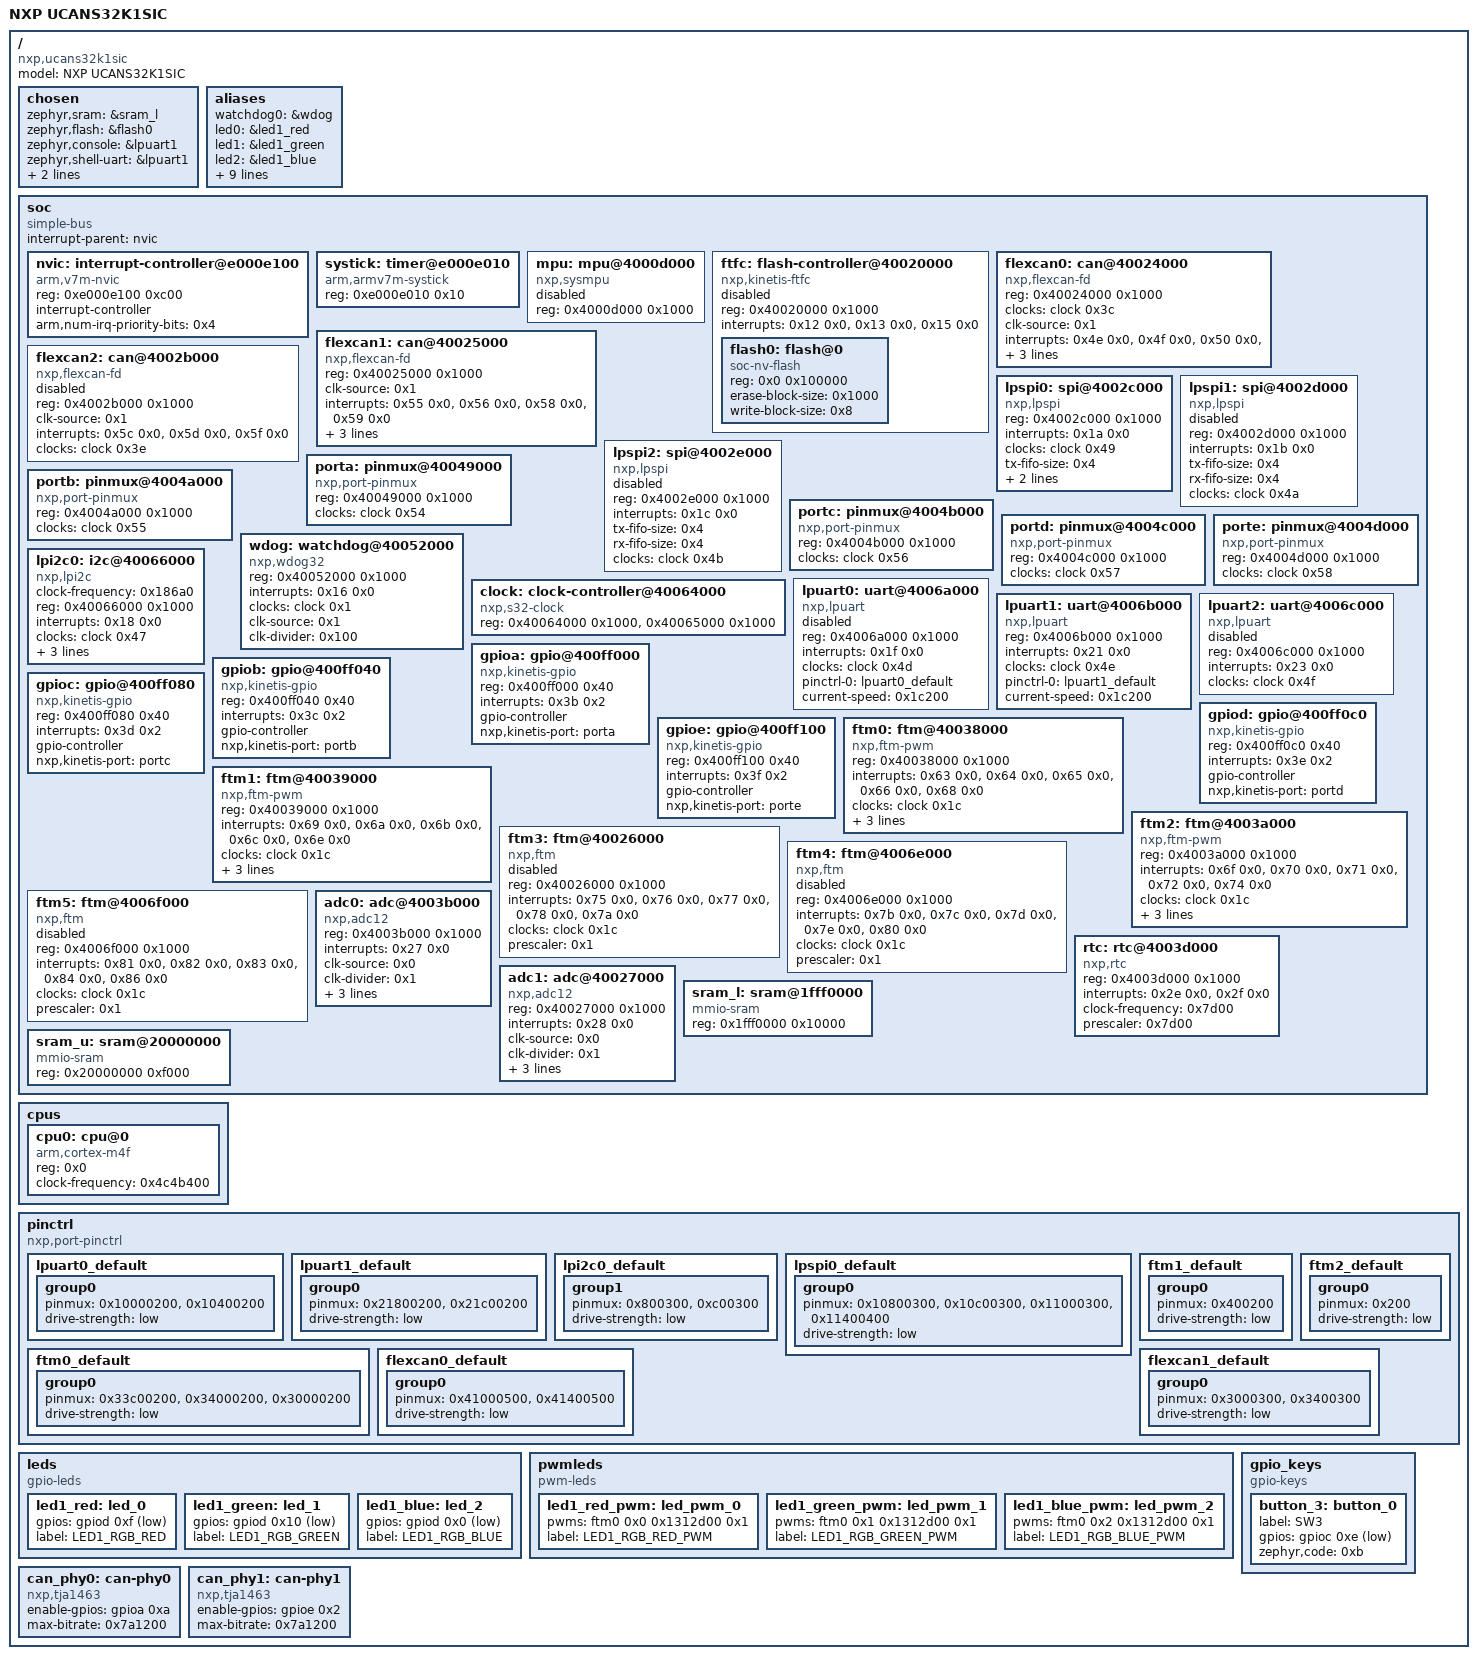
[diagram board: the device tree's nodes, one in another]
/dts-v1/;

/* node '/' defined in zephyr/dts/common/skeleton.dtsi:9 */
/ {
	#address-cells = < 0x1 >;        /* in zephyr/dts/common/skeleton.dtsi:10 */
	#size-cells = < 0x1 >;           /* in zephyr/dts/common/skeleton.dtsi:11 */
	model = "NXP UCANS32K1SIC";      /* in zephyr/boards/nxp/ucans32k1sic/ucans32k1sic.dts:15 */
	compatible = "nxp,ucans32k1sic"; /* in zephyr/boards/nxp/ucans32k1sic/ucans32k1sic.dts:16 */

	/* node '/chosen' defined in zephyr/dts/common/skeleton.dtsi:13 */
	chosen {
		zephyr,sram = &sram_l;        /* in zephyr/boards/nxp/ucans32k1sic/ucans32k1sic.dts:19 */
		zephyr,flash = &flash0;       /* in zephyr/boards/nxp/ucans32k1sic/ucans32k1sic.dts:20 */
		zephyr,console = &lpuart1;    /* in zephyr/boards/nxp/ucans32k1sic/ucans32k1sic.dts:21 */
		zephyr,shell-uart = &lpuart1; /* in zephyr/boards/nxp/ucans32k1sic/ucans32k1sic.dts:22 */
		zephyr,uart-pipe = &lpuart1;  /* in zephyr/boards/nxp/ucans32k1sic/ucans32k1sic.dts:23 */
		zephyr,canbus = &flexcan0;    /* in zephyr/boards/nxp/ucans32k1sic/ucans32k1sic.dts:24 */
	};

	/* node '/aliases' defined in zephyr/dts/common/skeleton.dtsi:15 */
	aliases {
		watchdog0 = &wdog;               /* in zephyr/dts/arm/nxp/nxp_s32k1xx.dtsi:14 */
		led0 = &led1_red;                /* in zephyr/boards/nxp/ucans32k1sic/ucans32k1sic.dts:28 */
		led1 = &led1_green;              /* in zephyr/boards/nxp/ucans32k1sic/ucans32k1sic.dts:29 */
		led2 = &led1_blue;               /* in zephyr/boards/nxp/ucans32k1sic/ucans32k1sic.dts:30 */
		pwm-led0 = &led1_red_pwm;        /* in zephyr/boards/nxp/ucans32k1sic/ucans32k1sic.dts:31 */
		pwm-led1 = &led1_green_pwm;      /* in zephyr/boards/nxp/ucans32k1sic/ucans32k1sic.dts:32 */
		pwm-led2 = &led1_blue_pwm;       /* in zephyr/boards/nxp/ucans32k1sic/ucans32k1sic.dts:33 */
		red-pwm-led = &led1_red_pwm;     /* in zephyr/boards/nxp/ucans32k1sic/ucans32k1sic.dts:34 */
		green-pwm-led = &led1_green_pwm; /* in zephyr/boards/nxp/ucans32k1sic/ucans32k1sic.dts:35 */
		blue-pwm-led = &led1_blue_pwm;   /* in zephyr/boards/nxp/ucans32k1sic/ucans32k1sic.dts:36 */
		pwm-0 = &ftm0;                   /* in zephyr/boards/nxp/ucans32k1sic/ucans32k1sic.dts:37 */
		sw0 = &button_3;                 /* in zephyr/boards/nxp/ucans32k1sic/ucans32k1sic.dts:38 */
		i2c-0 = &lpi2c0;                 /* in zephyr/boards/nxp/ucans32k1sic/ucans32k1sic.dts:39 */
	};

	/* node '/soc' defined in zephyr/dts/arm/armv7-m.dtsi:6 */
	soc {
		#address-cells = < 0x1 >;     /* in zephyr/dts/arm/armv7-m.dtsi:7 */
		#size-cells = < 0x1 >;        /* in zephyr/dts/arm/armv7-m.dtsi:8 */
		compatible = "simple-bus";    /* in zephyr/dts/arm/armv7-m.dtsi:9 */
		ranges;                       /* in zephyr/dts/arm/armv7-m.dtsi:11 */
		interrupt-parent = < &nvic >; /* in zephyr/dts/arm/nxp/nxp_s32k1xx.dtsi:34 */

		/* node '/soc/interrupt-controller@e000e100' defined in zephyr/dts/arm/armv7-m.dtsi:13 */
		nvic: interrupt-controller@e000e100 {
			#address-cells = < 0x1 >;            /* in zephyr/dts/arm/armv7-m.dtsi:14 */
			compatible = "arm,v7m-nvic";         /* in zephyr/dts/arm/armv7-m.dtsi:15 */
			reg = < 0xe000e100 0xc00 >;          /* in zephyr/dts/arm/armv7-m.dtsi:16 */
			interrupt-controller;                /* in zephyr/dts/arm/armv7-m.dtsi:17 */
			#interrupt-cells = < 0x2 >;          /* in zephyr/dts/arm/armv7-m.dtsi:18 */
			arm,num-irq-priority-bits = < 0x4 >; /* in zephyr/dts/arm/nxp/nxp_s32k146.dtsi:41 */
			phandle = < 0x1 >;                   /* in zephyr/dts/arm/nxp/nxp_s32k1xx.dtsi:34 */
		};

		/* node '/soc/timer@e000e010' defined in zephyr/dts/arm/armv7-m.dtsi:21 */
		systick: timer@e000e010 {
			compatible = "arm,armv7m-systick"; /* in zephyr/dts/arm/armv7-m.dtsi:22 */
			reg = < 0xe000e010 0x10 >;         /* in zephyr/dts/arm/armv7-m.dtsi:23 */
		};

		/* node '/soc/mpu@4000d000' defined in zephyr/dts/arm/nxp/nxp_s32k1xx.dtsi:36 */
		mpu: mpu@4000d000 {
			compatible = "nxp,sysmpu";   /* in zephyr/dts/arm/nxp/nxp_s32k1xx.dtsi:37 */
			reg = < 0x4000d000 0x1000 >; /* in zephyr/dts/arm/nxp/nxp_s32k1xx.dtsi:38 */
			status = "disabled";         /* in zephyr/dts/arm/nxp/nxp_s32k1xx.dtsi:39 */
		};

		/* node '/soc/flash-controller@40020000' defined in zephyr/dts/arm/nxp/nxp_s32k1xx.dtsi:42 */
		ftfc: flash-controller@40020000 {
			compatible = "nxp,kinetis-ftfc";      /* in zephyr/dts/arm/nxp/nxp_s32k1xx.dtsi:43 */
			reg = < 0x40020000 0x1000 >;          /* in zephyr/dts/arm/nxp/nxp_s32k1xx.dtsi:44 */
			interrupts = < 0x12 0x0 >,
			             < 0x13 0x0 >,
			             < 0x15 0x0 >;            /* in zephyr/dts/arm/nxp/nxp_s32k1xx.dtsi:45 */
			interrupt-names = "command-complete",
			                  "read-collision",
			                  "double-bit";       /* in zephyr/dts/arm/nxp/nxp_s32k1xx.dtsi:46 */
			#address-cells = < 0x1 >;             /* in zephyr/dts/arm/nxp/nxp_s32k1xx.dtsi:47 */
			#size-cells = < 0x1 >;                /* in zephyr/dts/arm/nxp/nxp_s32k1xx.dtsi:48 */
			status = "disabled";                  /* in zephyr/dts/arm/nxp/nxp_s32k1xx.dtsi:49 */

			/* node '/soc/flash-controller@40020000/flash@0' defined in zephyr/dts/arm/nxp/nxp_s32k146.dtsi:45 */
			flash0: flash@0 {
				compatible = "soc-nv-flash";   /* in zephyr/dts/arm/nxp/nxp_s32k146.dtsi:46 */
				reg = < 0x0 0x100000 >;        /* in zephyr/dts/arm/nxp/nxp_s32k146.dtsi:47 */
				erase-block-size = < 0x1000 >; /* in zephyr/dts/arm/nxp/nxp_s32k146.dtsi:48 */
				write-block-size = < 0x8 >;    /* in zephyr/dts/arm/nxp/nxp_s32k146.dtsi:49 */
			};
		};

		/* node '/soc/can@40024000' defined in zephyr/dts/arm/nxp/nxp_s32k1xx.dtsi:52 */
		flexcan0: can@40024000 {
			compatible = "nxp,flexcan-fd",
			             "nxp,flexcan";        /* in zephyr/dts/arm/nxp/nxp_s32k1xx.dtsi:53 */
			reg = < 0x40024000 0x1000 >;       /* in zephyr/dts/arm/nxp/nxp_s32k1xx.dtsi:54 */
			clocks = < &clock 0x3c >;          /* in zephyr/dts/arm/nxp/nxp_s32k1xx.dtsi:55 */
			clk-source = < 0x1 >;              /* in zephyr/dts/arm/nxp/nxp_s32k1xx.dtsi:56 */
			interrupts = < 0x4e 0x0 >,
			             < 0x4f 0x0 >,
			             < 0x50 0x0 >,
			             < 0x51 0x0 >,
			             < 0x52 0x0 >;         /* in zephyr/dts/arm/nxp/nxp_s32k146.dtsi:66 */
			interrupt-names = "warning",
			                  "error",
			                  "wake-up",
			                  "mb-0-15",
			                  "mb-16-31";      /* in zephyr/dts/arm/nxp/nxp_s32k146.dtsi:67 */
			pinctrl-0 = < &flexcan0_default >; /* in zephyr/boards/nxp/ucans32k1sic/ucans32k1sic.dts:187 */
			pinctrl-names = "default";         /* in zephyr/boards/nxp/ucans32k1sic/ucans32k1sic.dts:188 */
			phys = < &can_phy0 >;              /* in zephyr/boards/nxp/ucans32k1sic/ucans32k1sic.dts:189 */
			status = "okay";                   /* in zephyr/boards/nxp/ucans32k1sic/ucans32k1sic.dts:190 */
		};

		/* node '/soc/can@40025000' defined in zephyr/dts/arm/nxp/nxp_s32k1xx.dtsi:60 */
		flexcan1: can@40025000 {
			compatible = "nxp,flexcan-fd",
			             "nxp,flexcan";        /* in zephyr/dts/arm/nxp/nxp_s32k1xx.dtsi:61 */
			reg = < 0x40025000 0x1000 >;       /* in zephyr/dts/arm/nxp/nxp_s32k1xx.dtsi:62 */
			clk-source = < 0x1 >;              /* in zephyr/dts/arm/nxp/nxp_s32k1xx.dtsi:63 */
			interrupts = < 0x55 0x0 >,
			             < 0x56 0x0 >,
			             < 0x58 0x0 >,
			             < 0x59 0x0 >;         /* in zephyr/dts/arm/nxp/nxp_s32k146.dtsi:71 */
			interrupt-names = "warning",
			                  "error",
			                  "mb-0-15",
			                  "mb-16-31";      /* in zephyr/dts/arm/nxp/nxp_s32k146.dtsi:72 */
			clocks = < &clock 0x3d >;          /* in zephyr/dts/arm/nxp/nxp_s32k146.dtsi:73 */
			pinctrl-0 = < &flexcan1_default >; /* in zephyr/boards/nxp/ucans32k1sic/ucans32k1sic.dts:194 */
			pinctrl-names = "default";         /* in zephyr/boards/nxp/ucans32k1sic/ucans32k1sic.dts:195 */
			phys = < &can_phy1 >;              /* in zephyr/boards/nxp/ucans32k1sic/ucans32k1sic.dts:196 */
			status = "okay";                   /* in zephyr/boards/nxp/ucans32k1sic/ucans32k1sic.dts:197 */
		};

		/* node '/soc/can@4002b000' defined in zephyr/dts/arm/nxp/nxp_s32k1xx.dtsi:67 */
		flexcan2: can@4002b000 {
			compatible = "nxp,flexcan-fd",
			             "nxp,flexcan";    /* in zephyr/dts/arm/nxp/nxp_s32k1xx.dtsi:68 */
			reg = < 0x4002b000 0x1000 >;   /* in zephyr/dts/arm/nxp/nxp_s32k1xx.dtsi:69 */
			clk-source = < 0x1 >;          /* in zephyr/dts/arm/nxp/nxp_s32k1xx.dtsi:70 */
			status = "disabled";           /* in zephyr/dts/arm/nxp/nxp_s32k1xx.dtsi:71 */
			interrupts = < 0x5c 0x0 >,
			             < 0x5d 0x0 >,
			             < 0x5f 0x0 >;     /* in zephyr/dts/arm/nxp/nxp_s32k146.dtsi:77 */
			interrupt-names = "warning",
			                  "error",
			                  "mb-0-15";   /* in zephyr/dts/arm/nxp/nxp_s32k146.dtsi:78 */
			clocks = < &clock 0x3e >;      /* in zephyr/dts/arm/nxp/nxp_s32k146.dtsi:79 */
		};

		/* node '/soc/spi@4002c000' defined in zephyr/dts/arm/nxp/nxp_s32k1xx.dtsi:74 */
		lpspi0: spi@4002c000 {
			compatible = "nxp,lpspi";        /* in zephyr/dts/arm/nxp/nxp_s32k1xx.dtsi:75 */
			reg = < 0x4002c000 0x1000 >;     /* in zephyr/dts/arm/nxp/nxp_s32k1xx.dtsi:76 */
			interrupts = < 0x1a 0x0 >;       /* in zephyr/dts/arm/nxp/nxp_s32k1xx.dtsi:77 */
			clocks = < &clock 0x49 >;        /* in zephyr/dts/arm/nxp/nxp_s32k1xx.dtsi:78 */
			#address-cells = < 0x1 >;        /* in zephyr/dts/arm/nxp/nxp_s32k1xx.dtsi:79 */
			#size-cells = < 0x0 >;           /* in zephyr/dts/arm/nxp/nxp_s32k1xx.dtsi:80 */
			tx-fifo-size = < 0x4 >;          /* in zephyr/dts/arm/nxp/nxp_s32k1xx.dtsi:81 */
			rx-fifo-size = < 0x4 >;          /* in zephyr/dts/arm/nxp/nxp_s32k1xx.dtsi:82 */
			pinctrl-0 = < &lpspi0_default >; /* in zephyr/boards/nxp/ucans32k1sic/ucans32k1sic.dts:151 */
			pinctrl-names = "default";       /* in zephyr/boards/nxp/ucans32k1sic/ucans32k1sic.dts:152 */
			status = "okay";                 /* in zephyr/boards/nxp/ucans32k1sic/ucans32k1sic.dts:153 */
		};

		/* node '/soc/spi@4002d000' defined in zephyr/dts/arm/nxp/nxp_s32k1xx.dtsi:86 */
		lpspi1: spi@4002d000 {
			compatible = "nxp,lpspi";    /* in zephyr/dts/arm/nxp/nxp_s32k1xx.dtsi:87 */
			reg = < 0x4002d000 0x1000 >; /* in zephyr/dts/arm/nxp/nxp_s32k1xx.dtsi:88 */
			interrupts = < 0x1b 0x0 >;   /* in zephyr/dts/arm/nxp/nxp_s32k1xx.dtsi:89 */
			#address-cells = < 0x1 >;    /* in zephyr/dts/arm/nxp/nxp_s32k1xx.dtsi:90 */
			#size-cells = < 0x0 >;       /* in zephyr/dts/arm/nxp/nxp_s32k1xx.dtsi:91 */
			tx-fifo-size = < 0x4 >;      /* in zephyr/dts/arm/nxp/nxp_s32k1xx.dtsi:92 */
			rx-fifo-size = < 0x4 >;      /* in zephyr/dts/arm/nxp/nxp_s32k1xx.dtsi:93 */
			status = "disabled";         /* in zephyr/dts/arm/nxp/nxp_s32k1xx.dtsi:94 */
			clocks = < &clock 0x4a >;    /* in zephyr/dts/arm/nxp/nxp_s32k146.dtsi:58 */
		};

		/* node '/soc/spi@4002e000' defined in zephyr/dts/arm/nxp/nxp_s32k1xx.dtsi:97 */
		lpspi2: spi@4002e000 {
			compatible = "nxp,lpspi";    /* in zephyr/dts/arm/nxp/nxp_s32k1xx.dtsi:98 */
			reg = < 0x4002e000 0x1000 >; /* in zephyr/dts/arm/nxp/nxp_s32k1xx.dtsi:99 */
			interrupts = < 0x1c 0x0 >;   /* in zephyr/dts/arm/nxp/nxp_s32k1xx.dtsi:100 */
			#address-cells = < 0x1 >;    /* in zephyr/dts/arm/nxp/nxp_s32k1xx.dtsi:101 */
			#size-cells = < 0x0 >;       /* in zephyr/dts/arm/nxp/nxp_s32k1xx.dtsi:102 */
			tx-fifo-size = < 0x4 >;      /* in zephyr/dts/arm/nxp/nxp_s32k1xx.dtsi:103 */
			rx-fifo-size = < 0x4 >;      /* in zephyr/dts/arm/nxp/nxp_s32k1xx.dtsi:104 */
			status = "disabled";         /* in zephyr/dts/arm/nxp/nxp_s32k1xx.dtsi:105 */
			clocks = < &clock 0x4b >;    /* in zephyr/dts/arm/nxp/nxp_s32k146.dtsi:62 */
		};

		/* node '/soc/pinmux@40049000' defined in zephyr/dts/arm/nxp/nxp_s32k1xx.dtsi:108 */
		porta: pinmux@40049000 {
			compatible = "nxp,port-pinmux"; /* in zephyr/dts/arm/nxp/nxp_s32k1xx.dtsi:109 */
			reg = < 0x40049000 0x1000 >;    /* in zephyr/dts/arm/nxp/nxp_s32k1xx.dtsi:110 */
			clocks = < &clock 0x54 >;       /* in zephyr/dts/arm/nxp/nxp_s32k1xx.dtsi:111 */
			phandle = < 0xc >;              /* in zephyr/dts/arm/nxp/nxp_s32k1xx.dtsi:204 */
		};

		/* node '/soc/pinmux@4004a000' defined in zephyr/dts/arm/nxp/nxp_s32k1xx.dtsi:114 */
		portb: pinmux@4004a000 {
			compatible = "nxp,port-pinmux"; /* in zephyr/dts/arm/nxp/nxp_s32k1xx.dtsi:115 */
			reg = < 0x4004a000 0x1000 >;    /* in zephyr/dts/arm/nxp/nxp_s32k1xx.dtsi:116 */
			clocks = < &clock 0x55 >;       /* in zephyr/dts/arm/nxp/nxp_s32k1xx.dtsi:117 */
			phandle = < 0xd >;              /* in zephyr/dts/arm/nxp/nxp_s32k1xx.dtsi:214 */
		};

		/* node '/soc/pinmux@4004b000' defined in zephyr/dts/arm/nxp/nxp_s32k1xx.dtsi:120 */
		portc: pinmux@4004b000 {
			compatible = "nxp,port-pinmux"; /* in zephyr/dts/arm/nxp/nxp_s32k1xx.dtsi:121 */
			reg = < 0x4004b000 0x1000 >;    /* in zephyr/dts/arm/nxp/nxp_s32k1xx.dtsi:122 */
			clocks = < &clock 0x56 >;       /* in zephyr/dts/arm/nxp/nxp_s32k1xx.dtsi:123 */
			phandle = < 0xe >;              /* in zephyr/dts/arm/nxp/nxp_s32k1xx.dtsi:224 */
		};

		/* node '/soc/pinmux@4004c000' defined in zephyr/dts/arm/nxp/nxp_s32k1xx.dtsi:126 */
		portd: pinmux@4004c000 {
			compatible = "nxp,port-pinmux"; /* in zephyr/dts/arm/nxp/nxp_s32k1xx.dtsi:127 */
			reg = < 0x4004c000 0x1000 >;    /* in zephyr/dts/arm/nxp/nxp_s32k1xx.dtsi:128 */
			clocks = < &clock 0x57 >;       /* in zephyr/dts/arm/nxp/nxp_s32k1xx.dtsi:129 */
			phandle = < 0xf >;              /* in zephyr/dts/arm/nxp/nxp_s32k1xx.dtsi:234 */
		};

		/* node '/soc/pinmux@4004d000' defined in zephyr/dts/arm/nxp/nxp_s32k1xx.dtsi:132 */
		porte: pinmux@4004d000 {
			compatible = "nxp,port-pinmux"; /* in zephyr/dts/arm/nxp/nxp_s32k1xx.dtsi:133 */
			reg = < 0x4004d000 0x1000 >;    /* in zephyr/dts/arm/nxp/nxp_s32k1xx.dtsi:134 */
			clocks = < &clock 0x58 >;       /* in zephyr/dts/arm/nxp/nxp_s32k1xx.dtsi:135 */
			phandle = < 0x10 >;             /* in zephyr/dts/arm/nxp/nxp_s32k1xx.dtsi:244 */
		};

		/* node '/soc/watchdog@40052000' defined in zephyr/dts/arm/nxp/nxp_s32k1xx.dtsi:138 */
		wdog: watchdog@40052000 {
			compatible = "nxp,wdog32";   /* in zephyr/dts/arm/nxp/nxp_s32k1xx.dtsi:139 */
			reg = < 0x40052000 0x1000 >; /* in zephyr/dts/arm/nxp/nxp_s32k1xx.dtsi:140 */
			interrupts = < 0x16 0x0 >;   /* in zephyr/dts/arm/nxp/nxp_s32k1xx.dtsi:141 */
			clocks = < &clock 0x1 >;     /* in zephyr/dts/arm/nxp/nxp_s32k1xx.dtsi:142 */
			clk-source = < 0x1 >;        /* in zephyr/dts/arm/nxp/nxp_s32k1xx.dtsi:143 */
			clk-divider = < 0x100 >;     /* in zephyr/dts/arm/nxp/nxp_s32k1xx.dtsi:144 */
		};

		/* node '/soc/clock-controller@40064000' defined in zephyr/dts/arm/nxp/nxp_s32k1xx.dtsi:147 */
		clock: clock-controller@40064000 {
			compatible = "nxp,s32-clock"; /* in zephyr/dts/arm/nxp/nxp_s32k1xx.dtsi:148 */
			reg = < 0x40064000 0x1000 >,
			      < 0x40065000 0x1000 >;  /* in zephyr/dts/arm/nxp/nxp_s32k1xx.dtsi:149 */
			#clock-cells = < 0x1 >;       /* in zephyr/dts/arm/nxp/nxp_s32k1xx.dtsi:150 */
			status = "okay";              /* in zephyr/dts/arm/nxp/nxp_s32k1xx.dtsi:151 */
			phandle = < 0x2 >;            /* in zephyr/dts/arm/nxp/nxp_s32k1xx.dtsi:55 */
		};

		/* node '/soc/i2c@40066000' defined in zephyr/dts/arm/nxp/nxp_s32k1xx.dtsi:154 */
		lpi2c0: i2c@40066000 {
			compatible = "nxp,lpi2c";        /* in zephyr/dts/arm/nxp/nxp_s32k1xx.dtsi:155 */
			clock-frequency = < 0x186a0 >;   /* in zephyr/dts/arm/nxp/nxp_s32k1xx.dtsi:156 */
			#address-cells = < 0x1 >;        /* in zephyr/dts/arm/nxp/nxp_s32k1xx.dtsi:157 */
			#size-cells = < 0x0 >;           /* in zephyr/dts/arm/nxp/nxp_s32k1xx.dtsi:158 */
			reg = < 0x40066000 0x1000 >;     /* in zephyr/dts/arm/nxp/nxp_s32k1xx.dtsi:159 */
			interrupts = < 0x18 0x0 >;       /* in zephyr/dts/arm/nxp/nxp_s32k1xx.dtsi:160 */
			clocks = < &clock 0x47 >;        /* in zephyr/dts/arm/nxp/nxp_s32k1xx.dtsi:161 */
			pinctrl-0 = < &lpi2c0_default >; /* in zephyr/boards/nxp/ucans32k1sic/ucans32k1sic.dts:143 */
			pinctrl-names = "default";       /* in zephyr/boards/nxp/ucans32k1sic/ucans32k1sic.dts:144 */
			scl-gpios = < &gpioa 0x3 0x0 >;  /* in zephyr/boards/nxp/ucans32k1sic/ucans32k1sic.dts:145 */
			sda-gpios = < &gpioa 0x2 0x0 >;  /* in zephyr/boards/nxp/ucans32k1sic/ucans32k1sic.dts:146 */
			status = "okay";                 /* in zephyr/boards/nxp/ucans32k1sic/ucans32k1sic.dts:147 */
		};

		/* node '/soc/uart@4006a000' defined in zephyr/dts/arm/nxp/nxp_s32k1xx.dtsi:175 */
		lpuart0: uart@4006a000 {
			compatible = "nxp,lpuart";        /* in zephyr/dts/arm/nxp/nxp_s32k1xx.dtsi:176 */
			reg = < 0x4006a000 0x1000 >;      /* in zephyr/dts/arm/nxp/nxp_s32k1xx.dtsi:177 */
			interrupts = < 0x1f 0x0 >;        /* in zephyr/dts/arm/nxp/nxp_s32k1xx.dtsi:178 */
			clocks = < &clock 0x4d >;         /* in zephyr/dts/arm/nxp/nxp_s32k1xx.dtsi:179 */
			status = "disabled";              /* in zephyr/dts/arm/nxp/nxp_s32k1xx.dtsi:180 */
			pinctrl-0 = < &lpuart0_default >; /* in zephyr/boards/nxp/ucans32k1sic/ucans32k1sic.dts:130 */
			pinctrl-names = "default";        /* in zephyr/boards/nxp/ucans32k1sic/ucans32k1sic.dts:131 */
			current-speed = < 0x1c200 >;      /* in zephyr/boards/nxp/ucans32k1sic/ucans32k1sic.dts:132 */
		};

		/* node '/soc/uart@4006b000' defined in zephyr/dts/arm/nxp/nxp_s32k1xx.dtsi:183 */
		lpuart1: uart@4006b000 {
			compatible = "nxp,lpuart";        /* in zephyr/dts/arm/nxp/nxp_s32k1xx.dtsi:184 */
			reg = < 0x4006b000 0x1000 >;      /* in zephyr/dts/arm/nxp/nxp_s32k1xx.dtsi:185 */
			interrupts = < 0x21 0x0 >;        /* in zephyr/dts/arm/nxp/nxp_s32k1xx.dtsi:186 */
			clocks = < &clock 0x4e >;         /* in zephyr/dts/arm/nxp/nxp_s32k1xx.dtsi:187 */
			pinctrl-0 = < &lpuart1_default >; /* in zephyr/boards/nxp/ucans32k1sic/ucans32k1sic.dts:136 */
			pinctrl-names = "default";        /* in zephyr/boards/nxp/ucans32k1sic/ucans32k1sic.dts:137 */
			current-speed = < 0x1c200 >;      /* in zephyr/boards/nxp/ucans32k1sic/ucans32k1sic.dts:138 */
			status = "okay";                  /* in zephyr/boards/nxp/ucans32k1sic/ucans32k1sic.dts:139 */
		};

		/* node '/soc/uart@4006c000' defined in zephyr/dts/arm/nxp/nxp_s32k1xx.dtsi:191 */
		lpuart2: uart@4006c000 {
			compatible = "nxp,lpuart";   /* in zephyr/dts/arm/nxp/nxp_s32k1xx.dtsi:192 */
			reg = < 0x4006c000 0x1000 >; /* in zephyr/dts/arm/nxp/nxp_s32k1xx.dtsi:193 */
			interrupts = < 0x23 0x0 >;   /* in zephyr/dts/arm/nxp/nxp_s32k1xx.dtsi:194 */
			status = "disabled";         /* in zephyr/dts/arm/nxp/nxp_s32k1xx.dtsi:195 */
			clocks = < &clock 0x4f >;    /* in zephyr/dts/arm/nxp/nxp_s32k146.dtsi:54 */
		};

		/* node '/soc/gpio@400ff000' defined in zephyr/dts/arm/nxp/nxp_s32k1xx.dtsi:198 */
		gpioa: gpio@400ff000 {
			compatible = "nxp,kinetis-gpio"; /* in zephyr/dts/arm/nxp/nxp_s32k1xx.dtsi:199 */
			reg = < 0x400ff000 0x40 >;       /* in zephyr/dts/arm/nxp/nxp_s32k1xx.dtsi:200 */
			interrupts = < 0x3b 0x2 >;       /* in zephyr/dts/arm/nxp/nxp_s32k1xx.dtsi:201 */
			gpio-controller;                 /* in zephyr/dts/arm/nxp/nxp_s32k1xx.dtsi:202 */
			#gpio-cells = < 0x2 >;           /* in zephyr/dts/arm/nxp/nxp_s32k1xx.dtsi:203 */
			nxp,kinetis-port = < &porta >;   /* in zephyr/dts/arm/nxp/nxp_s32k1xx.dtsi:204 */
			status = "okay";                 /* in zephyr/boards/nxp/ucans32k1sic/ucans32k1sic.dts:110 */
			phandle = < 0x9 >;               /* in zephyr/boards/nxp/ucans32k1sic/ucans32k1sic.dts:145 */
		};

		/* node '/soc/gpio@400ff040' defined in zephyr/dts/arm/nxp/nxp_s32k1xx.dtsi:208 */
		gpiob: gpio@400ff040 {
			compatible = "nxp,kinetis-gpio"; /* in zephyr/dts/arm/nxp/nxp_s32k1xx.dtsi:209 */
			reg = < 0x400ff040 0x40 >;       /* in zephyr/dts/arm/nxp/nxp_s32k1xx.dtsi:210 */
			interrupts = < 0x3c 0x2 >;       /* in zephyr/dts/arm/nxp/nxp_s32k1xx.dtsi:211 */
			gpio-controller;                 /* in zephyr/dts/arm/nxp/nxp_s32k1xx.dtsi:212 */
			#gpio-cells = < 0x2 >;           /* in zephyr/dts/arm/nxp/nxp_s32k1xx.dtsi:213 */
			nxp,kinetis-port = < &portb >;   /* in zephyr/dts/arm/nxp/nxp_s32k1xx.dtsi:214 */
			status = "okay";                 /* in zephyr/boards/nxp/ucans32k1sic/ucans32k1sic.dts:114 */
		};

		/* node '/soc/gpio@400ff080' defined in zephyr/dts/arm/nxp/nxp_s32k1xx.dtsi:218 */
		gpioc: gpio@400ff080 {
			compatible = "nxp,kinetis-gpio"; /* in zephyr/dts/arm/nxp/nxp_s32k1xx.dtsi:219 */
			reg = < 0x400ff080 0x40 >;       /* in zephyr/dts/arm/nxp/nxp_s32k1xx.dtsi:220 */
			interrupts = < 0x3d 0x2 >;       /* in zephyr/dts/arm/nxp/nxp_s32k1xx.dtsi:221 */
			gpio-controller;                 /* in zephyr/dts/arm/nxp/nxp_s32k1xx.dtsi:222 */
			#gpio-cells = < 0x2 >;           /* in zephyr/dts/arm/nxp/nxp_s32k1xx.dtsi:223 */
			nxp,kinetis-port = < &portc >;   /* in zephyr/dts/arm/nxp/nxp_s32k1xx.dtsi:224 */
			status = "okay";                 /* in zephyr/boards/nxp/ucans32k1sic/ucans32k1sic.dts:118 */
			phandle = < 0x16 >;              /* in zephyr/boards/nxp/ucans32k1sic/ucans32k1sic.dts:85 */
		};

		/* node '/soc/gpio@400ff0c0' defined in zephyr/dts/arm/nxp/nxp_s32k1xx.dtsi:228 */
		gpiod: gpio@400ff0c0 {
			compatible = "nxp,kinetis-gpio"; /* in zephyr/dts/arm/nxp/nxp_s32k1xx.dtsi:229 */
			reg = < 0x400ff0c0 0x40 >;       /* in zephyr/dts/arm/nxp/nxp_s32k1xx.dtsi:230 */
			interrupts = < 0x3e 0x2 >;       /* in zephyr/dts/arm/nxp/nxp_s32k1xx.dtsi:231 */
			gpio-controller;                 /* in zephyr/dts/arm/nxp/nxp_s32k1xx.dtsi:232 */
			#gpio-cells = < 0x2 >;           /* in zephyr/dts/arm/nxp/nxp_s32k1xx.dtsi:233 */
			nxp,kinetis-port = < &portd >;   /* in zephyr/dts/arm/nxp/nxp_s32k1xx.dtsi:234 */
			status = "okay";                 /* in zephyr/boards/nxp/ucans32k1sic/ucans32k1sic.dts:122 */
			phandle = < 0x14 >;              /* in zephyr/boards/nxp/ucans32k1sic/ucans32k1sic.dts:46 */
		};

		/* node '/soc/gpio@400ff100' defined in zephyr/dts/arm/nxp/nxp_s32k1xx.dtsi:238 */
		gpioe: gpio@400ff100 {
			compatible = "nxp,kinetis-gpio"; /* in zephyr/dts/arm/nxp/nxp_s32k1xx.dtsi:239 */
			reg = < 0x400ff100 0x40 >;       /* in zephyr/dts/arm/nxp/nxp_s32k1xx.dtsi:240 */
			interrupts = < 0x3f 0x2 >;       /* in zephyr/dts/arm/nxp/nxp_s32k1xx.dtsi:241 */
			gpio-controller;                 /* in zephyr/dts/arm/nxp/nxp_s32k1xx.dtsi:242 */
			#gpio-cells = < 0x2 >;           /* in zephyr/dts/arm/nxp/nxp_s32k1xx.dtsi:243 */
			nxp,kinetis-port = < &porte >;   /* in zephyr/dts/arm/nxp/nxp_s32k1xx.dtsi:244 */
			status = "okay";                 /* in zephyr/boards/nxp/ucans32k1sic/ucans32k1sic.dts:126 */
			phandle = < 0x17 >;              /* in zephyr/boards/nxp/ucans32k1sic/ucans32k1sic.dts:99 */
		};

		/* node '/soc/ftm@40038000' defined in zephyr/dts/arm/nxp/nxp_s32k1xx.dtsi:248 */
		ftm0: ftm@40038000 {
			reg = < 0x40038000 0x1000 >;   /* in zephyr/dts/arm/nxp/nxp_s32k1xx.dtsi:250 */
			interrupts = < 0x63 0x0 >,
			             < 0x64 0x0 >,
			             < 0x65 0x0 >,
			             < 0x66 0x0 >,
			             < 0x68 0x0 >;     /* in zephyr/dts/arm/nxp/nxp_s32k1xx.dtsi:251 */
			interrupt-names = "0-1",
			                  "2-3",
			                  "4-5",
			                  "6-7",
			                  "overflow";  /* in zephyr/dts/arm/nxp/nxp_s32k1xx.dtsi:252 */
			clocks = < &clock 0x1c >;      /* in zephyr/dts/arm/nxp/nxp_s32k1xx.dtsi:253 */
			compatible = "nxp,ftm-pwm";    /* in zephyr/boards/nxp/ucans32k1sic/ucans32k1sic.dts:157 */
			pinctrl-0 = < &ftm0_default >; /* in zephyr/boards/nxp/ucans32k1sic/ucans32k1sic.dts:158 */
			pinctrl-names = "default";     /* in zephyr/boards/nxp/ucans32k1sic/ucans32k1sic.dts:159 */
			clock-source = "system";       /* in zephyr/boards/nxp/ucans32k1sic/ucans32k1sic.dts:160 */
			prescaler = < 0x4 >;           /* in zephyr/boards/nxp/ucans32k1sic/ucans32k1sic.dts:161 */
			#pwm-cells = < 0x3 >;          /* in zephyr/boards/nxp/ucans32k1sic/ucans32k1sic.dts:162 */
			status = "okay";               /* in zephyr/boards/nxp/ucans32k1sic/ucans32k1sic.dts:163 */
			phandle = < 0x15 >;            /* in zephyr/boards/nxp/ucans32k1sic/ucans32k1sic.dts:65 */
		};

		/* node '/soc/ftm@40039000' defined in zephyr/dts/arm/nxp/nxp_s32k1xx.dtsi:258 */
		ftm1: ftm@40039000 {
			reg = < 0x40039000 0x1000 >;   /* in zephyr/dts/arm/nxp/nxp_s32k1xx.dtsi:260 */
			interrupts = < 0x69 0x0 >,
			             < 0x6a 0x0 >,
			             < 0x6b 0x0 >,
			             < 0x6c 0x0 >,
			             < 0x6e 0x0 >;     /* in zephyr/dts/arm/nxp/nxp_s32k1xx.dtsi:261 */
			interrupt-names = "0-1",
			                  "2-3",
			                  "4-5",
			                  "6-7",
			                  "overflow";  /* in zephyr/dts/arm/nxp/nxp_s32k1xx.dtsi:262 */
			clocks = < &clock 0x1c >;      /* in zephyr/dts/arm/nxp/nxp_s32k1xx.dtsi:263 */
			compatible = "nxp,ftm-pwm";    /* in zephyr/boards/nxp/ucans32k1sic/ucans32k1sic.dts:167 */
			pinctrl-0 = < &ftm1_default >; /* in zephyr/boards/nxp/ucans32k1sic/ucans32k1sic.dts:168 */
			pinctrl-names = "default";     /* in zephyr/boards/nxp/ucans32k1sic/ucans32k1sic.dts:169 */
			clock-source = "system";       /* in zephyr/boards/nxp/ucans32k1sic/ucans32k1sic.dts:170 */
			prescaler = < 0x4 >;           /* in zephyr/boards/nxp/ucans32k1sic/ucans32k1sic.dts:171 */
			#pwm-cells = < 0x3 >;          /* in zephyr/boards/nxp/ucans32k1sic/ucans32k1sic.dts:172 */
			status = "okay";               /* in zephyr/boards/nxp/ucans32k1sic/ucans32k1sic.dts:173 */
		};

		/* node '/soc/ftm@4003a000' defined in zephyr/dts/arm/nxp/nxp_s32k1xx.dtsi:268 */
		ftm2: ftm@4003a000 {
			reg = < 0x4003a000 0x1000 >;   /* in zephyr/dts/arm/nxp/nxp_s32k1xx.dtsi:270 */
			interrupts = < 0x6f 0x0 >,
			             < 0x70 0x0 >,
			             < 0x71 0x0 >,
			             < 0x72 0x0 >,
			             < 0x74 0x0 >;     /* in zephyr/dts/arm/nxp/nxp_s32k1xx.dtsi:271 */
			interrupt-names = "0-1",
			                  "2-3",
			                  "4-5",
			                  "6-7",
			                  "overflow";  /* in zephyr/dts/arm/nxp/nxp_s32k1xx.dtsi:272 */
			clocks = < &clock 0x1c >;      /* in zephyr/dts/arm/nxp/nxp_s32k1xx.dtsi:273 */
			compatible = "nxp,ftm-pwm";    /* in zephyr/boards/nxp/ucans32k1sic/ucans32k1sic.dts:177 */
			pinctrl-0 = < &ftm2_default >; /* in zephyr/boards/nxp/ucans32k1sic/ucans32k1sic.dts:178 */
			pinctrl-names = "default";     /* in zephyr/boards/nxp/ucans32k1sic/ucans32k1sic.dts:179 */
			clock-source = "system";       /* in zephyr/boards/nxp/ucans32k1sic/ucans32k1sic.dts:180 */
			prescaler = < 0x4 >;           /* in zephyr/boards/nxp/ucans32k1sic/ucans32k1sic.dts:181 */
			#pwm-cells = < 0x3 >;          /* in zephyr/boards/nxp/ucans32k1sic/ucans32k1sic.dts:182 */
			status = "okay";               /* in zephyr/boards/nxp/ucans32k1sic/ucans32k1sic.dts:183 */
		};

		/* node '/soc/ftm@40026000' defined in zephyr/dts/arm/nxp/nxp_s32k1xx.dtsi:278 */
		ftm3: ftm@40026000 {
			compatible = "nxp,ftm";       /* in zephyr/dts/arm/nxp/nxp_s32k1xx.dtsi:279 */
			reg = < 0x40026000 0x1000 >;  /* in zephyr/dts/arm/nxp/nxp_s32k1xx.dtsi:280 */
			interrupts = < 0x75 0x0 >,
			             < 0x76 0x0 >,
			             < 0x77 0x0 >,
			             < 0x78 0x0 >,
			             < 0x7a 0x0 >;    /* in zephyr/dts/arm/nxp/nxp_s32k1xx.dtsi:281 */
			interrupt-names = "0-1",
			                  "2-3",
			                  "4-5",
			                  "6-7",
			                  "overflow"; /* in zephyr/dts/arm/nxp/nxp_s32k1xx.dtsi:282 */
			clocks = < &clock 0x1c >;     /* in zephyr/dts/arm/nxp/nxp_s32k1xx.dtsi:283 */
			prescaler = < 0x1 >;          /* in zephyr/dts/arm/nxp/nxp_s32k1xx.dtsi:284 */
			status = "disabled";          /* in zephyr/dts/arm/nxp/nxp_s32k1xx.dtsi:285 */
		};

		/* node '/soc/ftm@4006e000' defined in zephyr/dts/arm/nxp/nxp_s32k1xx.dtsi:288 */
		ftm4: ftm@4006e000 {
			compatible = "nxp,ftm";       /* in zephyr/dts/arm/nxp/nxp_s32k1xx.dtsi:289 */
			reg = < 0x4006e000 0x1000 >;  /* in zephyr/dts/arm/nxp/nxp_s32k1xx.dtsi:290 */
			interrupts = < 0x7b 0x0 >,
			             < 0x7c 0x0 >,
			             < 0x7d 0x0 >,
			             < 0x7e 0x0 >,
			             < 0x80 0x0 >;    /* in zephyr/dts/arm/nxp/nxp_s32k1xx.dtsi:291 */
			interrupt-names = "0-1",
			                  "2-3",
			                  "4-5",
			                  "6-7",
			                  "overflow"; /* in zephyr/dts/arm/nxp/nxp_s32k1xx.dtsi:292 */
			clocks = < &clock 0x1c >;     /* in zephyr/dts/arm/nxp/nxp_s32k1xx.dtsi:293 */
			prescaler = < 0x1 >;          /* in zephyr/dts/arm/nxp/nxp_s32k1xx.dtsi:294 */
			status = "disabled";          /* in zephyr/dts/arm/nxp/nxp_s32k1xx.dtsi:295 */
		};

		/* node '/soc/ftm@4006f000' defined in zephyr/dts/arm/nxp/nxp_s32k1xx.dtsi:298 */
		ftm5: ftm@4006f000 {
			compatible = "nxp,ftm";       /* in zephyr/dts/arm/nxp/nxp_s32k1xx.dtsi:299 */
			reg = < 0x4006f000 0x1000 >;  /* in zephyr/dts/arm/nxp/nxp_s32k1xx.dtsi:300 */
			interrupts = < 0x81 0x0 >,
			             < 0x82 0x0 >,
			             < 0x83 0x0 >,
			             < 0x84 0x0 >,
			             < 0x86 0x0 >;    /* in zephyr/dts/arm/nxp/nxp_s32k1xx.dtsi:301 */
			interrupt-names = "0-1",
			                  "2-3",
			                  "4-5",
			                  "6-7",
			                  "overflow"; /* in zephyr/dts/arm/nxp/nxp_s32k1xx.dtsi:302 */
			clocks = < &clock 0x1c >;     /* in zephyr/dts/arm/nxp/nxp_s32k1xx.dtsi:303 */
			prescaler = < 0x1 >;          /* in zephyr/dts/arm/nxp/nxp_s32k1xx.dtsi:304 */
			status = "disabled";          /* in zephyr/dts/arm/nxp/nxp_s32k1xx.dtsi:305 */
		};

		/* node '/soc/rtc@4003d000' defined in zephyr/dts/arm/nxp/nxp_s32k1xx.dtsi:328 */
		rtc: rtc@4003d000 {
			compatible = "nxp,rtc";       /* in zephyr/dts/arm/nxp/nxp_s32k1xx.dtsi:329 */
			reg = < 0x4003d000 0x1000 >;  /* in zephyr/dts/arm/nxp/nxp_s32k1xx.dtsi:330 */
			interrupts = < 0x2e 0x0 >,
			             < 0x2f 0x0 >;    /* in zephyr/dts/arm/nxp/nxp_s32k1xx.dtsi:331 */
			interrupt-names = "alarm",
			                  "seconds";  /* in zephyr/dts/arm/nxp/nxp_s32k1xx.dtsi:332 */
			clock-frequency = < 0x7d00 >; /* in zephyr/dts/arm/nxp/nxp_s32k1xx.dtsi:333 */
			prescaler = < 0x7d00 >;       /* in zephyr/dts/arm/nxp/nxp_s32k1xx.dtsi:334 */
		};

		/* node '/soc/adc@4003b000' defined in zephyr/dts/arm/nxp/nxp_s32k1xx.dtsi:337 */
		adc0: adc@4003b000 {
			compatible = "nxp,adc12";    /* in zephyr/dts/arm/nxp/nxp_s32k1xx.dtsi:338 */
			reg = < 0x4003b000 0x1000 >; /* in zephyr/dts/arm/nxp/nxp_s32k1xx.dtsi:339 */
			interrupts = < 0x27 0x0 >;   /* in zephyr/dts/arm/nxp/nxp_s32k1xx.dtsi:340 */
			clk-source = < 0x0 >;        /* in zephyr/dts/arm/nxp/nxp_s32k1xx.dtsi:341 */
			clk-divider = < 0x1 >;       /* in zephyr/dts/arm/nxp/nxp_s32k1xx.dtsi:342 */
			clocks = < &clock 0x32 >;    /* in zephyr/dts/arm/nxp/nxp_s32k1xx.dtsi:343 */
			#io-channel-cells = < 0x1 >; /* in zephyr/dts/arm/nxp/nxp_s32k1xx.dtsi:344 */
			sample-time = < 0x41 >;      /* in zephyr/boards/nxp/ucans32k1sic/ucans32k1sic.dts:201 */
			vref-mv = < 0xce4 >;         /* in zephyr/boards/nxp/ucans32k1sic/ucans32k1sic.dts:202 */
			status = "okay";             /* in zephyr/boards/nxp/ucans32k1sic/ucans32k1sic.dts:203 */
		};

		/* node '/soc/adc@40027000' defined in zephyr/dts/arm/nxp/nxp_s32k1xx.dtsi:348 */
		adc1: adc@40027000 {
			compatible = "nxp,adc12";    /* in zephyr/dts/arm/nxp/nxp_s32k1xx.dtsi:349 */
			reg = < 0x40027000 0x1000 >; /* in zephyr/dts/arm/nxp/nxp_s32k1xx.dtsi:350 */
			interrupts = < 0x28 0x0 >;   /* in zephyr/dts/arm/nxp/nxp_s32k1xx.dtsi:351 */
			clk-source = < 0x0 >;        /* in zephyr/dts/arm/nxp/nxp_s32k1xx.dtsi:352 */
			clk-divider = < 0x1 >;       /* in zephyr/dts/arm/nxp/nxp_s32k1xx.dtsi:353 */
			clocks = < &clock 0x33 >;    /* in zephyr/dts/arm/nxp/nxp_s32k1xx.dtsi:354 */
			#io-channel-cells = < 0x1 >; /* in zephyr/dts/arm/nxp/nxp_s32k1xx.dtsi:355 */
			sample-time = < 0x41 >;      /* in zephyr/boards/nxp/ucans32k1sic/ucans32k1sic.dts:207 */
			vref-mv = < 0xce4 >;         /* in zephyr/boards/nxp/ucans32k1sic/ucans32k1sic.dts:208 */
			status = "okay";             /* in zephyr/boards/nxp/ucans32k1sic/ucans32k1sic.dts:209 */
		};

		/* node '/soc/sram@1fff0000' defined in zephyr/dts/arm/nxp/nxp_s32k146.dtsi:24 */
		sram_l: sram@1fff0000 {
			compatible = "mmio-sram";     /* in zephyr/dts/arm/nxp/nxp_s32k146.dtsi:25 */
			reg = < 0x1fff0000 0x10000 >; /* in zephyr/dts/arm/nxp/nxp_s32k146.dtsi:26 */
		};

		/* node '/soc/sram@20000000' defined in zephyr/dts/arm/nxp/nxp_s32k146.dtsi:29 */
		sram_u: sram@20000000 {
			compatible = "mmio-sram";    /* in zephyr/dts/arm/nxp/nxp_s32k146.dtsi:30 */
			reg = < 0x20000000 0xf000 >; /* in zephyr/dts/arm/nxp/nxp_s32k146.dtsi:31 */
		};
	};

	/* node '/cpus' defined in zephyr/dts/arm/nxp/nxp_s32k1xx.dtsi:17 */
	cpus {
		#address-cells = < 0x1 >; /* in zephyr/dts/arm/nxp/nxp_s32k1xx.dtsi:18 */
		#size-cells = < 0x0 >;    /* in zephyr/dts/arm/nxp/nxp_s32k1xx.dtsi:19 */

		/* node '/cpus/cpu@0' defined in zephyr/dts/arm/nxp/nxp_s32k1xx.dtsi:21 */
		cpu0: cpu@0 {
			device_type = "cpu";             /* in zephyr/dts/arm/nxp/nxp_s32k1xx.dtsi:22 */
			reg = < 0x0 >;                   /* in zephyr/dts/arm/nxp/nxp_s32k1xx.dtsi:23 */
			compatible = "arm,cortex-m4f";   /* in zephyr/dts/arm/nxp/nxp_s32k146.dtsi:13 */
			clock-frequency = < 0x4c4b400 >; /* in zephyr/boards/nxp/ucans32k1sic/ucans32k1sic.dts:106 */
		};
	};

	/* node '/pinctrl' defined in zephyr/dts/arm/nxp/nxp_s32k1xx.dtsi:28 */
	pinctrl: pinctrl {
		compatible = "nxp,port-pinctrl"; /* in zephyr/dts/arm/nxp/nxp_s32k1xx.dtsi:29 */
		status = "okay";                 /* in zephyr/dts/arm/nxp/nxp_s32k1xx.dtsi:30 */

		/* node '/pinctrl/lpuart0_default' defined in zephyr/boards/nxp/ucans32k1sic/ucans32k1sic-pinctrl.dtsi:10 */
		lpuart0_default: lpuart0_default {
			phandle = < 0xa >; /* in zephyr/boards/nxp/ucans32k1sic/ucans32k1sic.dts:130 */

			/* node '/pinctrl/lpuart0_default/group0' defined in zephyr/boards/nxp/ucans32k1sic/ucans32k1sic-pinctrl.dtsi:11 */
			group0 {
				pinmux = < 0x10000200 >,
				         < 0x10400200 >; /* in zephyr/boards/nxp/ucans32k1sic/ucans32k1sic-pinctrl.dtsi:12 */
				drive-strength = "low";  /* in zephyr/boards/nxp/ucans32k1sic/ucans32k1sic-pinctrl.dtsi:13 */
			};
		};

		/* node '/pinctrl/lpuart1_default' defined in zephyr/boards/nxp/ucans32k1sic/ucans32k1sic-pinctrl.dtsi:17 */
		lpuart1_default: lpuart1_default {
			phandle = < 0xb >; /* in zephyr/boards/nxp/ucans32k1sic/ucans32k1sic.dts:136 */

			/* node '/pinctrl/lpuart1_default/group0' defined in zephyr/boards/nxp/ucans32k1sic/ucans32k1sic-pinctrl.dtsi:18 */
			group0 {
				pinmux = < 0x21800200 >,
				         < 0x21c00200 >; /* in zephyr/boards/nxp/ucans32k1sic/ucans32k1sic-pinctrl.dtsi:19 */
				drive-strength = "low";  /* in zephyr/boards/nxp/ucans32k1sic/ucans32k1sic-pinctrl.dtsi:20 */
			};
		};

		/* node '/pinctrl/lpi2c0_default' defined in zephyr/boards/nxp/ucans32k1sic/ucans32k1sic-pinctrl.dtsi:24 */
		lpi2c0_default: lpi2c0_default {
			phandle = < 0x8 >; /* in zephyr/boards/nxp/ucans32k1sic/ucans32k1sic.dts:143 */

			/* node '/pinctrl/lpi2c0_default/group1' defined in zephyr/boards/nxp/ucans32k1sic/ucans32k1sic-pinctrl.dtsi:25 */
			group1 {
				pinmux = < 0x800300 >,
				         < 0xc00300 >;  /* in zephyr/boards/nxp/ucans32k1sic/ucans32k1sic-pinctrl.dtsi:26 */
				drive-strength = "low"; /* in zephyr/boards/nxp/ucans32k1sic/ucans32k1sic-pinctrl.dtsi:27 */
			};
		};

		/* node '/pinctrl/lpspi0_default' defined in zephyr/boards/nxp/ucans32k1sic/ucans32k1sic-pinctrl.dtsi:31 */
		lpspi0_default: lpspi0_default {
			phandle = < 0x7 >; /* in zephyr/boards/nxp/ucans32k1sic/ucans32k1sic.dts:151 */

			/* node '/pinctrl/lpspi0_default/group0' defined in zephyr/boards/nxp/ucans32k1sic/ucans32k1sic-pinctrl.dtsi:32 */
			group0 {
				pinmux = < 0x10800300 >,
				         < 0x10c00300 >,
				         < 0x11000300 >,
				         < 0x11400400 >; /* in zephyr/boards/nxp/ucans32k1sic/ucans32k1sic-pinctrl.dtsi:33 */
				drive-strength = "low";  /* in zephyr/boards/nxp/ucans32k1sic/ucans32k1sic-pinctrl.dtsi:37 */
			};
		};

		/* node '/pinctrl/ftm0_default' defined in zephyr/boards/nxp/ucans32k1sic/ucans32k1sic-pinctrl.dtsi:41 */
		ftm0_default: ftm0_default {
			phandle = < 0x11 >; /* in zephyr/boards/nxp/ucans32k1sic/ucans32k1sic.dts:158 */

			/* node '/pinctrl/ftm0_default/group0' defined in zephyr/boards/nxp/ucans32k1sic/ucans32k1sic-pinctrl.dtsi:42 */
			group0 {
				pinmux = < 0x33c00200 >,
				         < 0x34000200 >,
				         < 0x30000200 >; /* in zephyr/boards/nxp/ucans32k1sic/ucans32k1sic-pinctrl.dtsi:43 */
				drive-strength = "low";  /* in zephyr/boards/nxp/ucans32k1sic/ucans32k1sic-pinctrl.dtsi:46 */
			};
		};

		/* node '/pinctrl/ftm1_default' defined in zephyr/boards/nxp/ucans32k1sic/ucans32k1sic-pinctrl.dtsi:50 */
		ftm1_default: ftm1_default {
			phandle = < 0x12 >; /* in zephyr/boards/nxp/ucans32k1sic/ucans32k1sic.dts:168 */

			/* node '/pinctrl/ftm1_default/group0' defined in zephyr/boards/nxp/ucans32k1sic/ucans32k1sic-pinctrl.dtsi:51 */
			group0 {
				pinmux = < 0x400200 >;  /* in zephyr/boards/nxp/ucans32k1sic/ucans32k1sic-pinctrl.dtsi:52 */
				drive-strength = "low"; /* in zephyr/boards/nxp/ucans32k1sic/ucans32k1sic-pinctrl.dtsi:53 */
			};
		};

		/* node '/pinctrl/ftm2_default' defined in zephyr/boards/nxp/ucans32k1sic/ucans32k1sic-pinctrl.dtsi:57 */
		ftm2_default: ftm2_default {
			phandle = < 0x13 >; /* in zephyr/boards/nxp/ucans32k1sic/ucans32k1sic.dts:178 */

			/* node '/pinctrl/ftm2_default/group0' defined in zephyr/boards/nxp/ucans32k1sic/ucans32k1sic-pinctrl.dtsi:58 */
			group0 {
				pinmux = < 0x200 >;     /* in zephyr/boards/nxp/ucans32k1sic/ucans32k1sic-pinctrl.dtsi:59 */
				drive-strength = "low"; /* in zephyr/boards/nxp/ucans32k1sic/ucans32k1sic-pinctrl.dtsi:60 */
			};
		};

		/* node '/pinctrl/flexcan0_default' defined in zephyr/boards/nxp/ucans32k1sic/ucans32k1sic-pinctrl.dtsi:64 */
		flexcan0_default: flexcan0_default {
			phandle = < 0x3 >; /* in zephyr/boards/nxp/ucans32k1sic/ucans32k1sic.dts:187 */

			/* node '/pinctrl/flexcan0_default/group0' defined in zephyr/boards/nxp/ucans32k1sic/ucans32k1sic-pinctrl.dtsi:65 */
			group0 {
				pinmux = < 0x41000500 >,
				         < 0x41400500 >; /* in zephyr/boards/nxp/ucans32k1sic/ucans32k1sic-pinctrl.dtsi:66 */
				drive-strength = "low";  /* in zephyr/boards/nxp/ucans32k1sic/ucans32k1sic-pinctrl.dtsi:67 */
			};
		};

		/* node '/pinctrl/flexcan1_default' defined in zephyr/boards/nxp/ucans32k1sic/ucans32k1sic-pinctrl.dtsi:71 */
		flexcan1_default: flexcan1_default {
			phandle = < 0x5 >; /* in zephyr/boards/nxp/ucans32k1sic/ucans32k1sic.dts:194 */

			/* node '/pinctrl/flexcan1_default/group0' defined in zephyr/boards/nxp/ucans32k1sic/ucans32k1sic-pinctrl.dtsi:72 */
			group0 {
				pinmux = < 0x3000300 >,
				         < 0x3400300 >; /* in zephyr/boards/nxp/ucans32k1sic/ucans32k1sic-pinctrl.dtsi:73 */
				drive-strength = "low"; /* in zephyr/boards/nxp/ucans32k1sic/ucans32k1sic-pinctrl.dtsi:74 */
			};
		};
	};

	/* node '/leds' defined in zephyr/boards/nxp/ucans32k1sic/ucans32k1sic.dts:42 */
	leds {
		compatible = "gpio-leds"; /* in zephyr/boards/nxp/ucans32k1sic/ucans32k1sic.dts:43 */

		/* node '/leds/led_0' defined in zephyr/boards/nxp/ucans32k1sic/ucans32k1sic.dts:45 */
		led1_red: led_0 {
			gpios = < &gpiod 0xf 0x1 >; /* in zephyr/boards/nxp/ucans32k1sic/ucans32k1sic.dts:46 */
			label = "LED1_RGB_RED";     /* in zephyr/boards/nxp/ucans32k1sic/ucans32k1sic.dts:47 */
		};

		/* node '/leds/led_1' defined in zephyr/boards/nxp/ucans32k1sic/ucans32k1sic.dts:50 */
		led1_green: led_1 {
			gpios = < &gpiod 0x10 0x1 >; /* in zephyr/boards/nxp/ucans32k1sic/ucans32k1sic.dts:51 */
			label = "LED1_RGB_GREEN";    /* in zephyr/boards/nxp/ucans32k1sic/ucans32k1sic.dts:52 */
		};

		/* node '/leds/led_2' defined in zephyr/boards/nxp/ucans32k1sic/ucans32k1sic.dts:55 */
		led1_blue: led_2 {
			gpios = < &gpiod 0x0 0x1 >; /* in zephyr/boards/nxp/ucans32k1sic/ucans32k1sic.dts:56 */
			label = "LED1_RGB_BLUE";    /* in zephyr/boards/nxp/ucans32k1sic/ucans32k1sic.dts:57 */
		};
	};

	/* node '/pwmleds' defined in zephyr/boards/nxp/ucans32k1sic/ucans32k1sic.dts:61 */
	pwmleds {
		compatible = "pwm-leds"; /* in zephyr/boards/nxp/ucans32k1sic/ucans32k1sic.dts:62 */

		/* node '/pwmleds/led_pwm_0' defined in zephyr/boards/nxp/ucans32k1sic/ucans32k1sic.dts:64 */
		led1_red_pwm: led_pwm_0 {
			pwms = < &ftm0 0x0 0x1312d00 0x1 >; /* in zephyr/boards/nxp/ucans32k1sic/ucans32k1sic.dts:65 */
			label = "LED1_RGB_RED_PWM";         /* in zephyr/boards/nxp/ucans32k1sic/ucans32k1sic.dts:66 */
		};

		/* node '/pwmleds/led_pwm_1' defined in zephyr/boards/nxp/ucans32k1sic/ucans32k1sic.dts:69 */
		led1_green_pwm: led_pwm_1 {
			pwms = < &ftm0 0x1 0x1312d00 0x1 >; /* in zephyr/boards/nxp/ucans32k1sic/ucans32k1sic.dts:70 */
			label = "LED1_RGB_GREEN_PWM";       /* in zephyr/boards/nxp/ucans32k1sic/ucans32k1sic.dts:71 */
		};

		/* node '/pwmleds/led_pwm_2' defined in zephyr/boards/nxp/ucans32k1sic/ucans32k1sic.dts:74 */
		led1_blue_pwm: led_pwm_2 {
			pwms = < &ftm0 0x2 0x1312d00 0x1 >; /* in zephyr/boards/nxp/ucans32k1sic/ucans32k1sic.dts:75 */
			label = "LED1_RGB_BLUE_PWM";        /* in zephyr/boards/nxp/ucans32k1sic/ucans32k1sic.dts:76 */
		};
	};

	/* node '/gpio_keys' defined in zephyr/boards/nxp/ucans32k1sic/ucans32k1sic.dts:80 */
	gpio_keys {
		compatible = "gpio-keys"; /* in zephyr/boards/nxp/ucans32k1sic/ucans32k1sic.dts:81 */

		/* node '/gpio_keys/button_0' defined in zephyr/boards/nxp/ucans32k1sic/ucans32k1sic.dts:83 */
		button_3: button_0 {
			label = "SW3";              /* in zephyr/boards/nxp/ucans32k1sic/ucans32k1sic.dts:84 */
			gpios = < &gpioc 0xe 0x1 >; /* in zephyr/boards/nxp/ucans32k1sic/ucans32k1sic.dts:85 */
			zephyr,code = < 0xb >;      /* in zephyr/boards/nxp/ucans32k1sic/ucans32k1sic.dts:86 */
		};
	};

	/* node '/can-phy0' defined in zephyr/boards/nxp/ucans32k1sic/ucans32k1sic.dts:90 */
	can_phy0: can-phy0 {
		compatible = "nxp,tja1463",
		             "nxp,tja1443",
		             "nxp,tja1153",
		             "can-transceiver-gpio"; /* in zephyr/boards/nxp/ucans32k1sic/ucans32k1sic.dts:91 */
		enable-gpios = < &gpioa 0xa 0x0 >;   /* in zephyr/boards/nxp/ucans32k1sic/ucans32k1sic.dts:92 */
		max-bitrate = < 0x7a1200 >;          /* in zephyr/boards/nxp/ucans32k1sic/ucans32k1sic.dts:93 */
		#phy-cells = < 0x0 >;                /* in zephyr/boards/nxp/ucans32k1sic/ucans32k1sic.dts:94 */
		phandle = < 0x4 >;                   /* in zephyr/boards/nxp/ucans32k1sic/ucans32k1sic.dts:189 */
	};

	/* node '/can-phy1' defined in zephyr/boards/nxp/ucans32k1sic/ucans32k1sic.dts:97 */
	can_phy1: can-phy1 {
		compatible = "nxp,tja1463",
		             "nxp,tja1443",
		             "nxp,tja1153",
		             "can-transceiver-gpio"; /* in zephyr/boards/nxp/ucans32k1sic/ucans32k1sic.dts:98 */
		enable-gpios = < &gpioe 0x2 0x0 >;   /* in zephyr/boards/nxp/ucans32k1sic/ucans32k1sic.dts:99 */
		max-bitrate = < 0x7a1200 >;          /* in zephyr/boards/nxp/ucans32k1sic/ucans32k1sic.dts:100 */
		#phy-cells = < 0x0 >;                /* in zephyr/boards/nxp/ucans32k1sic/ucans32k1sic.dts:101 */
		phandle = < 0x6 >;                   /* in zephyr/boards/nxp/ucans32k1sic/ucans32k1sic.dts:196 */
	};
};
